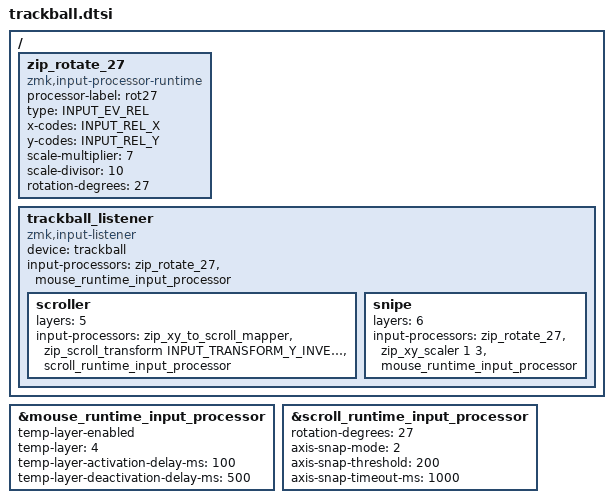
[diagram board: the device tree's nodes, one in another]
/ {
    zip_rotate_27: zip_rotate_27 {
        compatible = "zmk,input-processor-runtime";
        processor-label = "rot27";
        #input-processor-cells = <0>;
        type = <INPUT_EV_REL>;
        x-codes = <INPUT_REL_X>;
        y-codes = <INPUT_REL_Y>;
        scale-multiplier = <7>;
        scale-divisor = <10>;
        rotation-degrees = <27>;
    };

    trackball_listener {
        status = "okay";
        compatible = "zmk,input-listener";
        device = <&trackball>;
        input-processors = <&zip_rotate_27 &mouse_runtime_input_processor>;

        scroller {
            layers = <5>;
            input-processors =
                <&zip_xy_to_scroll_mapper>,
                <&zip_scroll_transform INPUT_TRANSFORM_Y_INVERT>,
                <&scroll_runtime_input_processor>;
        };

        snipe {
            layers = <6>;
            input-processors = <&zip_rotate_27 &zip_xy_scaler 1 3 &mouse_runtime_input_processor>;
        };
    };
};

&mouse_runtime_input_processor {
    temp-layer-enabled;
    temp-layer = <4>;
    temp-layer-activation-delay-ms = <100>;
    temp-layer-deactivation-delay-ms = <500>;
};

&scroll_runtime_input_processor {
    rotation-degrees = <27>;
    axis-snap-mode = <2>;
    axis-snap-threshold = <200>;
    axis-snap-timeout-ms = <1000>;
};
